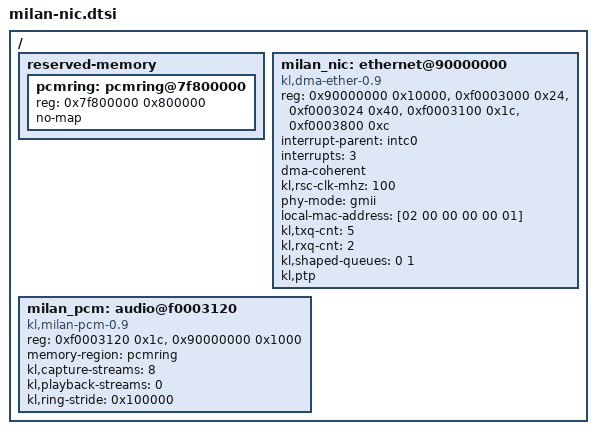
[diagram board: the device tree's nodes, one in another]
// SPDX-License-Identifier: (GPL-2.0 OR MIT)
/*
 * Milan TSN NIC + PCM nodes - GENERATED by
 * sw/builder/endstation_builder.py. DO NOT EDIT BY HAND;
 * edit configs/endstation_ax7101_8x8.yaml and regenerate.
 *
 * Board ax7101, rx_queues 2: the DMA
 * window map is a FUNCTION of the queue count (a 2-queue build
 * inserts steer + rx1 = 0x74 bytes before dma-ts). A DTB built
 * against the other count maps every window onto the wrong
 * registers - rebuild DTB + opensbi with the gateware.
 */

/ {
	reserved-memory {
		#address-cells = <1>;
		#size-cells    = <1>;
		ranges;

		pcmring: pcmring@7f800000 {
			reg = <0x7f800000 0x800000>;
			no-map;
		};
	};

	milan_nic: ethernet@90000000 {
		compatible = "kl,dma-ether-0.9", "kl,dma-ether";
		reg = <0x90000000 0x10000>,        /* csr    control plane */
		      <0xf0003000 0x24>,          /* dma-tx */
		      <0xf0003024 0x40>,          /* dma-rx */
		      <0xf0003100 0x1c>,          /* dma-ts */
		      <0xf0003800 0xc>;           /* phy  crg_reset + MDIO */
		reg-names = "csr", "dma-tx", "dma-rx", "dma-ts", "phy";
		interrupt-parent = <&intc0>;
		interrupts = <3>;
		interrupt-names = "csr";
		dma-coherent;
		kl,rsc-clk-mhz = <100>;	/* datapath clock (PHC rate + RSC timing) */
		phy-mode = "gmii";
		local-mac-address = [02 00 00 00 00 01];
		kl,txq-cnt = <5>;
		kl,rxq-cnt = <2>;
		kl,shaped-queues = <0 1>;
		kl,ptp;
		status = "okay";
	};

	milan_pcm: audio@f0003120 {
		compatible = "kl,milan-pcm-0.9", "kl,milan-pcm";
		reg = <0xf0003120 0x1c>,
		      <0x90000000 0x1000>;
		reg-names = "pcm-dma", "milan-csr";
		memory-region = <&pcmring>;
		kl,capture-streams = <8>;
		kl,playback-streams = <0>;
		kl,ring-stride = <0x100000>;
		status = "okay";
	};
};
